# AT32F421xx_v2 register map
Vendor: Keil; Series: AT32F421; File version: 1.0
CPU: CM4 r0p1, little endian, no MPU, FPU, 4 interrupt priority bits
Registers are 32-bit, read-write, reset 0x0 unless marked. A register's access mark holds for its fields unless they carry their own. Offsets are from the block's base; [hi:lo] are bit positions; {n}, {i} and the like mark numbered series; 'fields as' and 'values as' point back to an identical list.

## GPIOA — General purpose I/Os
Base 0x48000000
Same registers: GPIOB 0x48000400, GPIOC 0x48000800, GPIOF 0x48001400
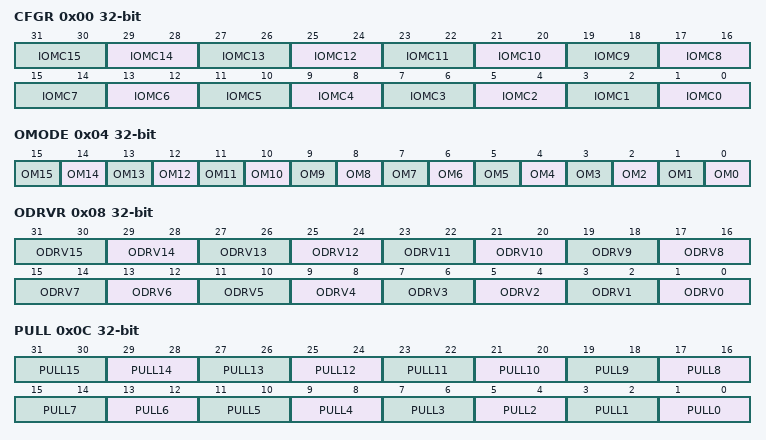
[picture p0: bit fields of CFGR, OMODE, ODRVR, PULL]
0x00 CFGR — GPIO configuration register
  [2n+1:2n] IOMC{n} (n=0..15) — GPIOx pin {n} mode configurate
0x04 OMODE — GPIO output mode register
  [n] OM{n} (n=0..15) — GPIOx pin {n} outpu mode configurate
0x08 ODRVR — GPIO drive capability register
  [2n+1:2n] ODRV{n} (n=0..15) — GPIOx pin {n} output drive capability
0x0C PULL — GPIO pull-up/pull-down register
  [2n+1:2n] PULL{n} (n=0..15) — GPIOx pin {n} pull configuration
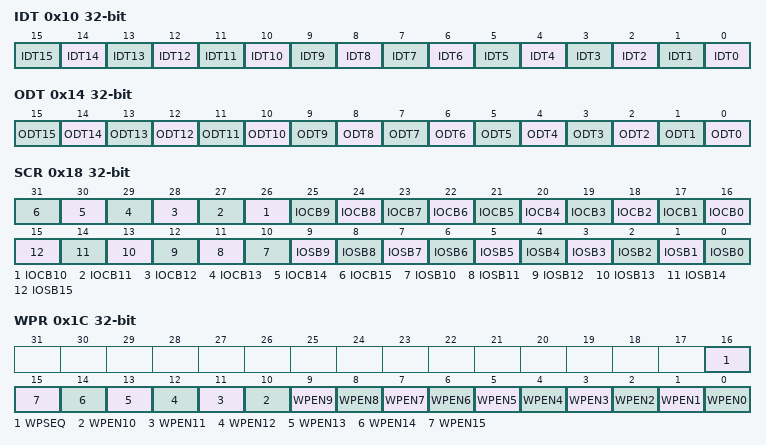
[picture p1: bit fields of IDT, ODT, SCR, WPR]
0x10 IDT ro — GPIO input data register
  [n] IDT{n} (n=0..15) — Port input data
0x14 ODT — GPIO output data register
  [n] ODT{n} (n=0..15) — Port output data
0x18 SCR wo — Port bit set/clear register
  [n+16] IOCB{n} (n=0..15) — Clear bit {n}
  [n] IOSB{n} (n=3..15) — Set bit {n}
  [2] IOSB2 — Set bit 1
  [1] IOSB1 — Set bit 1
  [0] IOSB0 — Set bit 0
0x1C WPR — Port write protect register
  [16] WPSEQ — Write protect sequence
  [n] WPEN{n} (n=0..15) — Write protect enable {n}
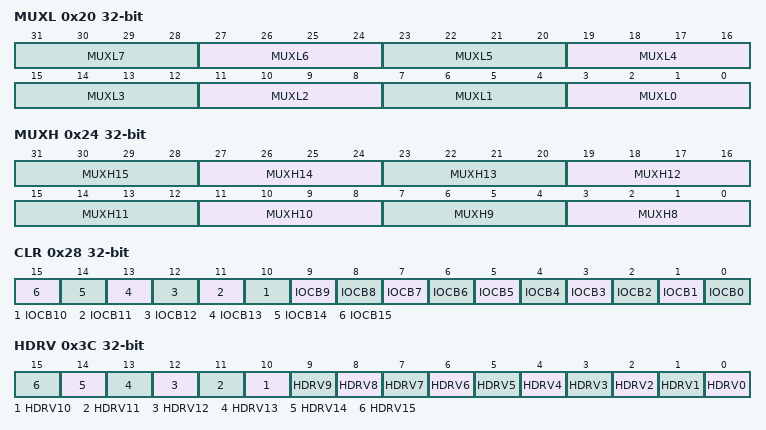
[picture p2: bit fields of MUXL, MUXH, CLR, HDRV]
0x20 MUXL — GPIO muxing function low register
  [4n+3:4n] MUXL{n} (n=0..7) — GPIOx pin {n} muxing
0x24 MUXH — GPIO muxing function high register
  [4n-29:4n-32] MUXH{n} (n=8..15) — GPIOx pin {n} muxing
0x28 CLR wo — GPIO bit reset register
  [n] IOCB{n} (n=3..15) — Clear bit {n}
  [2] IOCB2 — Clear bit 1
  [1] IOCB1 — Clear bit 1
  [0] IOCB0 — Clear bit 0
0x3C HDRV — Huge current driver
  [n] HDRV{n} (n=0..15) — Port x driver bit y

## EXINT
Base 0x40010400
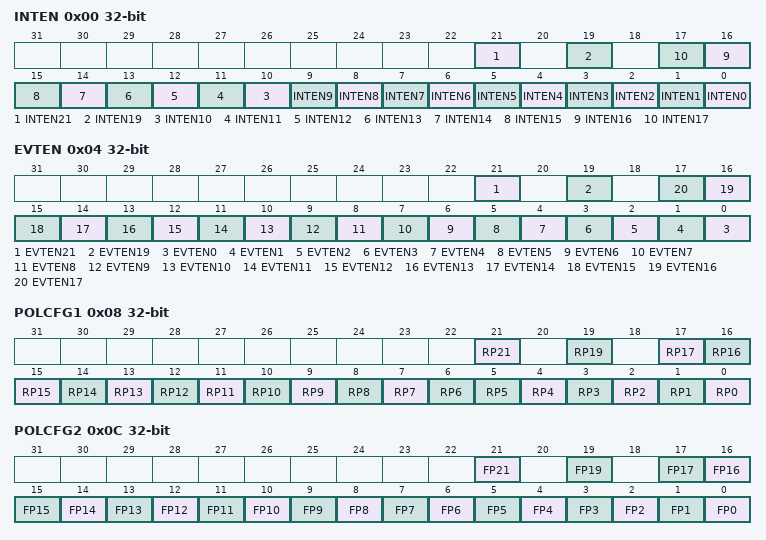
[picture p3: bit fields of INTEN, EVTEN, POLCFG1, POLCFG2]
0x00 INTEN — Interrupt enable register (EXTINT_INTEN)
  [21] INTEN21 — Interrupt enable or disable on line 21
  [19] INTEN19 — Interrupt enable or disable on line 19
  [n] INTEN{n} (n=0..17) — Interrupt enable or disable on line {n}
0x04 EVTEN — Event enable register (EXTINT_EVTEN)
  [21] EVTEN21 — Event enable or disable on line 21
  [19] EVTEN19 — Event enable or disable on line 19
  [n] EVTEN{n} (n=0..17) — Event enable or disable on line {n}
0x08 POLCFG1 — Rising polarity configuration register(EXTINT_POLCFG1)
  [21] RP21 — Rising polarity configuration bit of line 21
  [19] RP19 — Rising polarity configuration bit of line 19
  [n] RP{n} (n=7..17) — Rising polarity configuration bit of line {n}
  [6] RP6 — Rising polarity configuration bit of linee 6
  [n] RP{n} (n=0..5) — Rising polarity configuration bit of line {n}
0x0C POLCFG2 — Falling polarity configuration register(EXTINT_POLCFG2)
  [21] FP21 — Falling polarity event configuration bit of line 21
  [19] FP19 — Falling polarity event configuration bit of line 19
  [n] FP{n} (n=0..17) — Falling polarity event configuration bit of line {n}
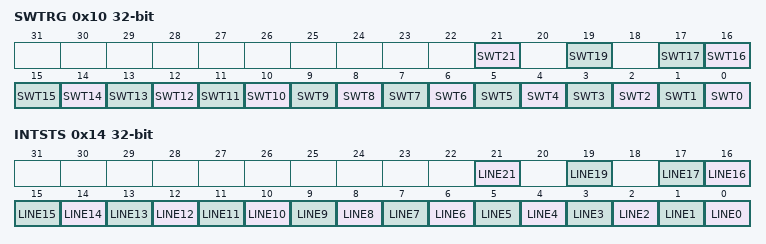
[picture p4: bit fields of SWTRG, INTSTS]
0x10 SWTRG — Software triggle register (EXTINT_SWIE)
  [21] SWT21 — Software triggle on line 21
  [19] SWT19 — Software triggle on line 19
  [n] SWT{n} (n=0..17) — Software triggle on line {n}
0x14 INTSTS — Interrupt status register (EXTINT_INTSTS)
  [21] LINE21 — Line 21 state bit
  [19] LINE19 — Line 19 state bit
  [n] LINE{n} (n=0..17) — Line {n} state bit

## DMA1 — DMA controller
Base 0x40020000
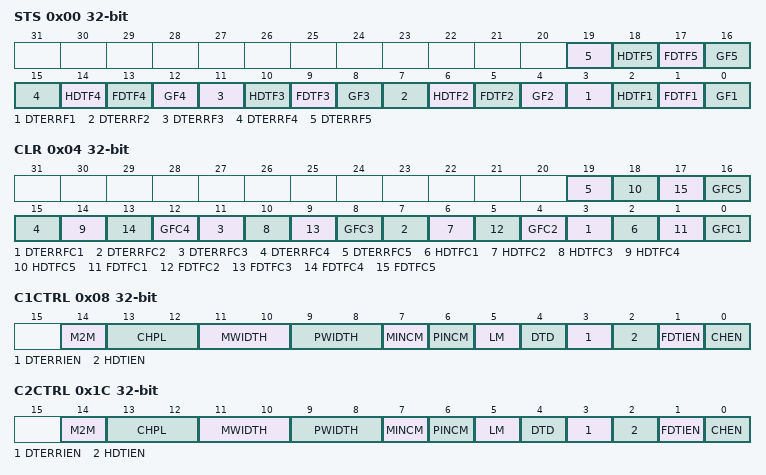
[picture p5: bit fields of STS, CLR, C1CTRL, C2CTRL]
0x00 STS ro — DMA status register (DMA_STS)
  [4n-1] DTERRF{n} (n=1..5) — Channel {n} data transfer error event flag
  [4n-2] HDTF{n} (n=1..5) — Channel {n} half data transfer event flag
  [4n-3] FDTF{n} (n=1..5) — Channel {n} full data transfer event flag
  [4n-4] GF{n} (n=1..5) — Channel {n} Global event flag
0x04 CLR — DMA flag clear register (DMA_CLR)
  [4n-1] DTERRFC{n} (n=1..5) — Channel {n} data transfer error flag clear
  [4n-2] HDTFC{n} (n=1..5) — Channel {n} half data transfer flag clear
  [4n-3] FDTFC{n} (n=1..5) — Channel {n} full data transfer flag clear
  [4n-4] GFC{n} (n=1..5) — Channel {n} Global flag clear
0x08 C1CTRL — DMA channel configuration register
  [14] M2M — Memory to memory mode
  [13:12] CHPL — Channel Priority level
  [11:10] MWIDTH — Memory data bit width
  [9:8] PWIDTH — Peripheral data bit width
  [7] MINCM — Memory address increment mode
  [6] PINCM — Peripheral address increment mode
  [5] LM — Loop mode
  [4] DTD — Data transfer direction
  [3] DTERRIEN — Data transfer error interrupt enable
  [2] HDTIEN — Half data transfer interrupt enable
  [1] FDTIEN — Full data transfer interrupt enable
  [0] CHEN — Channel enable
0x0C C1DTCNT — DMA channel 1 number of data to transfer register
  [15:0] CNT — Number of data to transfer
0x10 C1PADDR — DMA channel 1 peripheral base address register
  [31:0] PADDR — Peripheral address
{0x0+0x14*i} C{i}MADDR (i=1..5) — DMA channel {i} memory base address register
  [31:0] MADDR — Memory address
0x1C C2CTRL — DMA channel configuration register
  fields as C1CTRL
0x20 C2DTCNT — DMA channel 2 number of data to transfer register
  [15:0] CNT — Number of data to transfer
0x24 C2PADDR — DMA channel 2 peripheral base address register
  [31:0] PADDR — Peripheral address
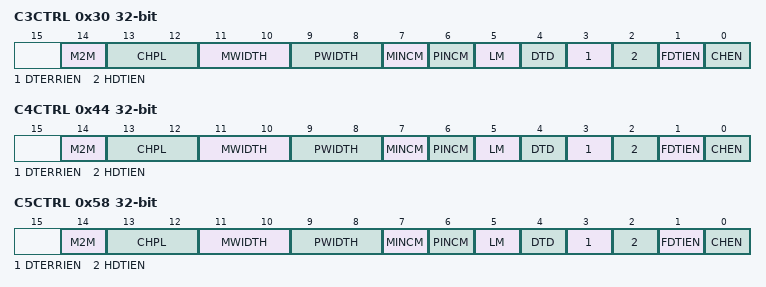
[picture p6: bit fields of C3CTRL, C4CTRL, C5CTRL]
0x30 C3CTRL — DMA channel configuration register
  fields as C1CTRL
0x34 C3DTCNT — DMA channel 3 number of data to transfer register
  [15:0] CNT — Number of data to transfer
0x38 C3PADDR — DMA channel 3 peripheral base address register
  [31:0] PADDR — Peripheral address
0x44 C4CTRL — DMA channel configuration register
  fields as C1CTRL
0x48 C4DTCNT — DMA channel 4 number of data to transfer register
  [15:0] CNT — Number of data to transfer
0x4C C4PADDR — DMA channel 4 peripheral base address register
  [31:0] PADDR — Peripheral address
0x58 C5CTRL — DMA channel configuration register
  fields as C1CTRL
0x5C C5DTCNT — DMA channel 5 number of data to transfer register
  [15:0] CNT — Number of data to transfer
0x60 C5PADDR — DMA channel 5 peripheral base address register
  [31:0] PADDR — Peripheral address

## Notices in the file
Copyright (C) 2012-2014 ARM Limited. All rights reserved.
Purpose: System Viewer Description (SVD) Example (Schema Version 1.1)
This is a description of a none-existent and incomplete device
for demonstration purposes only.
Redistribution and use in source and binary forms, with or without
modification, are permitted provided that the following conditions are met:
- Redistributions of source code must retain the above copyright
notice, this list of conditions and the following disclaimer.
- Redistributions in binary form must reproduce the above copyright
notice, this list of conditions and the following disclaimer in the
documentation and/or other materials provided with the distribution.
- Neither the name of ARM nor the names of its contributors may be used
to endorse or promote products derived from this software without
specific prior written permission.
THIS SOFTWARE IS PROVIDED BY THE COPYRIGHT HOLDERS AND CONTRIBUTORS "AS IS"
AND ANY EXPRESS OR IMPLIED WARRANTIES, INCLUDING, BUT NOT LIMITED TO, THE
IMPLIED WARRANTIES OF MERCHANTABILITY AND FITNESS FOR A PARTICULAR PURPOSE
ARE DISCLAIMED. IN NO EVENT SHALL COPYRIGHT HOLDERS AND CONTRIBUTORS BE
LIABLE FOR ANY DIRECT, INDIRECT, INCIDENTAL, SPECIAL, EXEMPLARY, OR
CONSEQUENTIAL DAMAGES (INCLUDING, BUT NOT LIMITED TO, PROCUREMENT OF
SUBSTITUTE GOODS OR SERVICES; LOSS OF USE, DATA, OR PROFITS; OR BUSINESS
INTERRUPTION) HOWEVER CAUSED AND ON ANY THEORY OF LIABILITY, WHETHER IN
CONTRACT, STRICT LIABILITY, OR TORT (INCLUDING NEGLIGENCE OR OTHERWISE)
ARISING IN ANY WAY OUT OF THE USE OF THIS SOFTWARE, EVEN IF ADVISED OF THE
POSSIBILITY OF SUCH DAMAGE.
